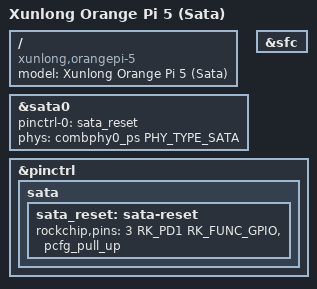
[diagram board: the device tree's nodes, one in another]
// SPDX-License-Identifier: (GPL-2.0+ OR MIT)

/dts-v1/;

#include "rk3588s-orangepi-5.dtsi"
#include <dt-bindings/pinctrl/rockchip.h>
#include <dt-bindings/gpio/gpio.h>

 / {
	model = "Xunlong Orange Pi 5 (Sata)";
	compatible = "xunlong,orangepi-5", "rockchip,rk3588s";
};

&sata0 {
	pinctrl-names = "default";
	pinctrl-0 = <&sata_reset>;
	status = "okay";

	phys = <&combphy0_ps PHY_TYPE_SATA>;
	phy-names = "sata-phy";
};

&sfc {
	status = "okay";
};

&pinctrl {
	sata {
		sata_reset: sata-reset {
			rockchip,pins = <3 RK_PD1 RK_FUNC_GPIO &pcfg_pull_up>;
		};
	};
};
